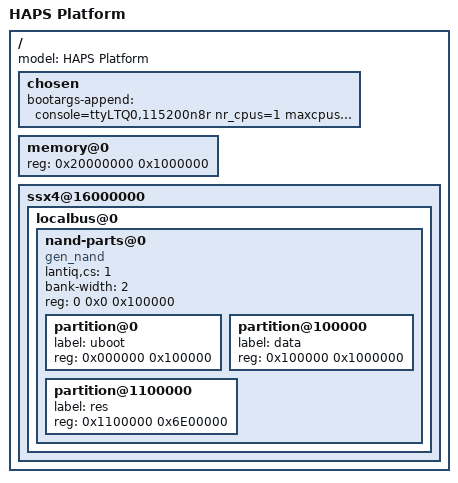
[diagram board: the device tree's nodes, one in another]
/dts-v1/;

/include/ "HAPS.dtsi"

/ {

	model = "HAPS Platform";

	chosen {
		bootargs-append = "console=ttyLTQ0,115200n8r nr_cpus=1 maxcpus=1 root=/dev/ram rw init=/etc/preinit mtdparts=ifx_nand:1024k(uboot),5m(kernel),20m(rootfs),-(res) loglevel=8 shell";
        };

	memory@0 {
		reg = <0x20000000 0x1000000>;
	};

	ssx4@16000000 {
			localbus@0 {
			ranges = <0 0 0x1c00000 0xfffff>;
			nand-parts@0 {
				compatible = "gen_nand", "lantiq,nand-xway";
				lantiq,cs = <1>;
				bank-width = <2>;
				reg = <0 0x0 0x100000>;
				#address-cells = <1>;
				#size-cells = <1>;

				partition@0 {
					label = "uboot";
					reg = <0x000000 0x100000>;
				};

				partition@100000 {
					label = "data";
					reg = <0x100000 0x1000000>;
				};	
				
				partition@1100000 { 
					label = "res";
					reg = <0x1100000 0x6E00000>;
				};
			};
		};
	};
};
